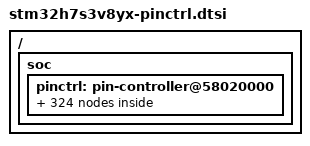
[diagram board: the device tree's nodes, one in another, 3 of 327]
/*
 * NOTE: Autogenerated file using genpinctrl.py
 *
 * SPDX-License-Identifier: Apache-2.0
 */

#include <zephyr/dt-bindings/pinctrl/stm32-pinctrl.h>

/ {
	soc {
		pinctrl: pin-controller@58020000 {

			/* ADC_IN / ADC_INN / ADC_INP */

			/omit-if-no-ref/ adc1_inn1_pa0: adc1_inn1_pa0 {
				pinmux = <STM32_PINMUX('A', 0, ANALOG)>;
			};

			/omit-if-no-ref/ adc1_inp0_pa0: adc1_inp0_pa0 {
				pinmux = <STM32_PINMUX('A', 0, ANALOG)>;
			};

			/omit-if-no-ref/ adc1_inp1_pa1: adc1_inp1_pa1 {
				pinmux = <STM32_PINMUX('A', 1, ANALOG)>;
			};

			/omit-if-no-ref/ adc1_inp14_pa2: adc1_inp14_pa2 {
				pinmux = <STM32_PINMUX('A', 2, ANALOG)>;
			};

			/omit-if-no-ref/ adc1_inp18_pa4: adc1_inp18_pa4 {
				pinmux = <STM32_PINMUX('A', 4, ANALOG)>;
			};

			/omit-if-no-ref/ adc1_inp3_pa6: adc1_inp3_pa6 {
				pinmux = <STM32_PINMUX('A', 6, ANALOG)>;
			};

			/omit-if-no-ref/ adc1_inn3_pa7: adc1_inn3_pa7 {
				pinmux = <STM32_PINMUX('A', 7, ANALOG)>;
			};

			/omit-if-no-ref/ adc1_inp7_pa7: adc1_inp7_pa7 {
				pinmux = <STM32_PINMUX('A', 7, ANALOG)>;
			};

			/omit-if-no-ref/ adc1_inn5_pb0: adc1_inn5_pb0 {
				pinmux = <STM32_PINMUX('B', 0, ANALOG)>;
			};

			/omit-if-no-ref/ adc1_inp9_pb0: adc1_inp9_pb0 {
				pinmux = <STM32_PINMUX('B', 0, ANALOG)>;
			};

			/omit-if-no-ref/ adc1_inp5_pb1: adc1_inp5_pb1 {
				pinmux = <STM32_PINMUX('B', 1, ANALOG)>;
			};

			/omit-if-no-ref/ adc1_inp10_pc0: adc1_inp10_pc0 {
				pinmux = <STM32_PINMUX('C', 0, ANALOG)>;
			};

			/omit-if-no-ref/ adc1_inn10_pc1: adc1_inn10_pc1 {
				pinmux = <STM32_PINMUX('C', 1, ANALOG)>;
			};

			/omit-if-no-ref/ adc1_inp11_pc1: adc1_inp11_pc1 {
				pinmux = <STM32_PINMUX('C', 1, ANALOG)>;
			};

			/omit-if-no-ref/ adc2_inn1_pa0: adc2_inn1_pa0 {
				pinmux = <STM32_PINMUX('A', 0, ANALOG)>;
			};

			/omit-if-no-ref/ adc2_inp0_pa0: adc2_inp0_pa0 {
				pinmux = <STM32_PINMUX('A', 0, ANALOG)>;
			};

			/omit-if-no-ref/ adc2_inp1_pa1: adc2_inp1_pa1 {
				pinmux = <STM32_PINMUX('A', 1, ANALOG)>;
			};

			/omit-if-no-ref/ adc2_inp14_pa2: adc2_inp14_pa2 {
				pinmux = <STM32_PINMUX('A', 2, ANALOG)>;
			};

			/omit-if-no-ref/ adc2_inp18_pa5: adc2_inp18_pa5 {
				pinmux = <STM32_PINMUX('A', 5, ANALOG)>;
			};

			/omit-if-no-ref/ adc2_inp3_pa6: adc2_inp3_pa6 {
				pinmux = <STM32_PINMUX('A', 6, ANALOG)>;
			};

			/omit-if-no-ref/ adc2_inn3_pa7: adc2_inn3_pa7 {
				pinmux = <STM32_PINMUX('A', 7, ANALOG)>;
			};

			/omit-if-no-ref/ adc2_inp7_pa7: adc2_inp7_pa7 {
				pinmux = <STM32_PINMUX('A', 7, ANALOG)>;
			};

			/omit-if-no-ref/ adc2_inn5_pb0: adc2_inn5_pb0 {
				pinmux = <STM32_PINMUX('B', 0, ANALOG)>;
			};

			/omit-if-no-ref/ adc2_inp9_pb0: adc2_inp9_pb0 {
				pinmux = <STM32_PINMUX('B', 0, ANALOG)>;
			};

			/omit-if-no-ref/ adc2_inp5_pb1: adc2_inp5_pb1 {
				pinmux = <STM32_PINMUX('B', 1, ANALOG)>;
			};

			/omit-if-no-ref/ adc2_inp10_pc0: adc2_inp10_pc0 {
				pinmux = <STM32_PINMUX('C', 0, ANALOG)>;
			};

			/omit-if-no-ref/ adc2_inn10_pc1: adc2_inn10_pc1 {
				pinmux = <STM32_PINMUX('C', 1, ANALOG)>;
			};

			/omit-if-no-ref/ adc2_inp11_pc1: adc2_inp11_pc1 {
				pinmux = <STM32_PINMUX('C', 1, ANALOG)>;
			};

			/* Analog */

			/omit-if-no-ref/ analog_pa0: analog_pa0 {
				pinmux = <STM32_PINMUX('A', 0, ANALOG)>;
			};

			/omit-if-no-ref/ analog_pa1: analog_pa1 {
				pinmux = <STM32_PINMUX('A', 1, ANALOG)>;
			};

			/omit-if-no-ref/ analog_pa2: analog_pa2 {
				pinmux = <STM32_PINMUX('A', 2, ANALOG)>;
			};

			/omit-if-no-ref/ analog_pa4: analog_pa4 {
				pinmux = <STM32_PINMUX('A', 4, ANALOG)>;
			};

			/omit-if-no-ref/ analog_pa5: analog_pa5 {
				pinmux = <STM32_PINMUX('A', 5, ANALOG)>;
			};

			/omit-if-no-ref/ analog_pa6: analog_pa6 {
				pinmux = <STM32_PINMUX('A', 6, ANALOG)>;
			};

			/omit-if-no-ref/ analog_pa7: analog_pa7 {
				pinmux = <STM32_PINMUX('A', 7, ANALOG)>;
			};

			/omit-if-no-ref/ analog_pa8: analog_pa8 {
				pinmux = <STM32_PINMUX('A', 8, ANALOG)>;
			};

			/omit-if-no-ref/ analog_pa9: analog_pa9 {
				pinmux = <STM32_PINMUX('A', 9, ANALOG)>;
			};

			/omit-if-no-ref/ analog_pa10: analog_pa10 {
				pinmux = <STM32_PINMUX('A', 10, ANALOG)>;
			};

			/omit-if-no-ref/ analog_pa11: analog_pa11 {
				pinmux = <STM32_PINMUX('A', 11, ANALOG)>;
			};

			/omit-if-no-ref/ analog_pa12: analog_pa12 {
				pinmux = <STM32_PINMUX('A', 12, ANALOG)>;
			};

			/omit-if-no-ref/ analog_pa13: analog_pa13 {
				pinmux = <STM32_PINMUX('A', 13, ANALOG)>;
			};

			/omit-if-no-ref/ analog_pa14: analog_pa14 {
				pinmux = <STM32_PINMUX('A', 14, ANALOG)>;
			};

			/omit-if-no-ref/ analog_pa15: analog_pa15 {
				pinmux = <STM32_PINMUX('A', 15, ANALOG)>;
			};

			/omit-if-no-ref/ analog_pb0: analog_pb0 {
				pinmux = <STM32_PINMUX('B', 0, ANALOG)>;
			};

			/omit-if-no-ref/ analog_pb1: analog_pb1 {
				pinmux = <STM32_PINMUX('B', 1, ANALOG)>;
			};

			/omit-if-no-ref/ analog_pb2: analog_pb2 {
				pinmux = <STM32_PINMUX('B', 2, ANALOG)>;
			};

			/omit-if-no-ref/ analog_pb3: analog_pb3 {
				pinmux = <STM32_PINMUX('B', 3, ANALOG)>;
			};

			/omit-if-no-ref/ analog_pb4: analog_pb4 {
				pinmux = <STM32_PINMUX('B', 4, ANALOG)>;
			};

			/omit-if-no-ref/ analog_pb5: analog_pb5 {
				pinmux = <STM32_PINMUX('B', 5, ANALOG)>;
			};

			/omit-if-no-ref/ analog_pb6: analog_pb6 {
				pinmux = <STM32_PINMUX('B', 6, ANALOG)>;
			};

			/omit-if-no-ref/ analog_pb7: analog_pb7 {
				pinmux = <STM32_PINMUX('B', 7, ANALOG)>;
			};

			/omit-if-no-ref/ analog_pb8: analog_pb8 {
				pinmux = <STM32_PINMUX('B', 8, ANALOG)>;
			};

			/omit-if-no-ref/ analog_pb10: analog_pb10 {
				pinmux = <STM32_PINMUX('B', 10, ANALOG)>;
			};

			/omit-if-no-ref/ analog_pb11: analog_pb11 {
				pinmux = <STM32_PINMUX('B', 11, ANALOG)>;
			};

			/omit-if-no-ref/ analog_pb12: analog_pb12 {
				pinmux = <STM32_PINMUX('B', 12, ANALOG)>;
			};

			/omit-if-no-ref/ analog_pb14: analog_pb14 {
				pinmux = <STM32_PINMUX('B', 14, ANALOG)>;
			};

			/omit-if-no-ref/ analog_pb15: analog_pb15 {
				pinmux = <STM32_PINMUX('B', 15, ANALOG)>;
			};

			/omit-if-no-ref/ analog_pc0: analog_pc0 {
				pinmux = <STM32_PINMUX('C', 0, ANALOG)>;
			};

			/omit-if-no-ref/ analog_pc1: analog_pc1 {
				pinmux = <STM32_PINMUX('C', 1, ANALOG)>;
			};

			/omit-if-no-ref/ analog_pc10: analog_pc10 {
				pinmux = <STM32_PINMUX('C', 10, ANALOG)>;
			};

			/omit-if-no-ref/ analog_pc11: analog_pc11 {
				pinmux = <STM32_PINMUX('C', 11, ANALOG)>;
			};

			/omit-if-no-ref/ analog_pc13: analog_pc13 {
				pinmux = <STM32_PINMUX('C', 13, ANALOG)>;
			};

			/omit-if-no-ref/ analog_pc14: analog_pc14 {
				pinmux = <STM32_PINMUX('C', 14, ANALOG)>;
			};

			/omit-if-no-ref/ analog_pc15: analog_pc15 {
				pinmux = <STM32_PINMUX('C', 15, ANALOG)>;
			};

			/omit-if-no-ref/ analog_pd7: analog_pd7 {
				pinmux = <STM32_PINMUX('D', 7, ANALOG)>;
			};

			/omit-if-no-ref/ analog_pd12: analog_pd12 {
				pinmux = <STM32_PINMUX('D', 12, ANALOG)>;
			};

			/omit-if-no-ref/ analog_ph0: analog_ph0 {
				pinmux = <STM32_PINMUX('H', 0, ANALOG)>;
			};

			/omit-if-no-ref/ analog_ph1: analog_ph1 {
				pinmux = <STM32_PINMUX('H', 1, ANALOG)>;
			};

			/omit-if-no-ref/ analog_pm0: analog_pm0 {
				pinmux = <STM32_PINMUX('M', 0, ANALOG)>;
			};

			/omit-if-no-ref/ analog_pm1: analog_pm1 {
				pinmux = <STM32_PINMUX('M', 1, ANALOG)>;
			};

			/omit-if-no-ref/ analog_pm2: analog_pm2 {
				pinmux = <STM32_PINMUX('M', 2, ANALOG)>;
			};

			/omit-if-no-ref/ analog_pm3: analog_pm3 {
				pinmux = <STM32_PINMUX('M', 3, ANALOG)>;
			};

			/omit-if-no-ref/ analog_pm5: analog_pm5 {
				pinmux = <STM32_PINMUX('M', 5, ANALOG)>;
			};

			/omit-if-no-ref/ analog_pm6: analog_pm6 {
				pinmux = <STM32_PINMUX('M', 6, ANALOG)>;
			};

			/omit-if-no-ref/ analog_pm8: analog_pm8 {
				pinmux = <STM32_PINMUX('M', 8, ANALOG)>;
			};

			/omit-if-no-ref/ analog_pm9: analog_pm9 {
				pinmux = <STM32_PINMUX('M', 9, ANALOG)>;
			};

			/omit-if-no-ref/ analog_pm11: analog_pm11 {
				pinmux = <STM32_PINMUX('M', 11, ANALOG)>;
			};

			/omit-if-no-ref/ analog_pm12: analog_pm12 {
				pinmux = <STM32_PINMUX('M', 12, ANALOG)>;
			};

			/omit-if-no-ref/ analog_pm13: analog_pm13 {
				pinmux = <STM32_PINMUX('M', 13, ANALOG)>;
			};

			/omit-if-no-ref/ analog_pm14: analog_pm14 {
				pinmux = <STM32_PINMUX('M', 14, ANALOG)>;
			};

			/omit-if-no-ref/ analog_po0: analog_po0 {
				pinmux = <STM32_PINMUX('O', 0, ANALOG)>;
			};

			/omit-if-no-ref/ analog_po1: analog_po1 {
				pinmux = <STM32_PINMUX('O', 1, ANALOG)>;
			};

			/omit-if-no-ref/ analog_po2: analog_po2 {
				pinmux = <STM32_PINMUX('O', 2, ANALOG)>;
			};

			/omit-if-no-ref/ analog_po4: analog_po4 {
				pinmux = <STM32_PINMUX('O', 4, ANALOG)>;
			};

			/omit-if-no-ref/ analog_po5: analog_po5 {
				pinmux = <STM32_PINMUX('O', 5, ANALOG)>;
			};

			/omit-if-no-ref/ analog_pp0: analog_pp0 {
				pinmux = <STM32_PINMUX('P', 0, ANALOG)>;
			};

			/omit-if-no-ref/ analog_pp1: analog_pp1 {
				pinmux = <STM32_PINMUX('P', 1, ANALOG)>;
			};

			/omit-if-no-ref/ analog_pp2: analog_pp2 {
				pinmux = <STM32_PINMUX('P', 2, ANALOG)>;
			};

			/omit-if-no-ref/ analog_pp3: analog_pp3 {
				pinmux = <STM32_PINMUX('P', 3, ANALOG)>;
			};

			/omit-if-no-ref/ analog_pp4: analog_pp4 {
				pinmux = <STM32_PINMUX('P', 4, ANALOG)>;
			};

			/omit-if-no-ref/ analog_pp5: analog_pp5 {
				pinmux = <STM32_PINMUX('P', 5, ANALOG)>;
			};

			/omit-if-no-ref/ analog_pp6: analog_pp6 {
				pinmux = <STM32_PINMUX('P', 6, ANALOG)>;
			};

			/omit-if-no-ref/ analog_pp7: analog_pp7 {
				pinmux = <STM32_PINMUX('P', 7, ANALOG)>;
			};

			/* FDCAN_RX */

			/omit-if-no-ref/ fdcan1_rx_pa11: fdcan1_rx_pa11 {
				pinmux = <STM32_PINMUX('A', 11, AF9)>;
			};

			/omit-if-no-ref/ fdcan1_rx_pb8: fdcan1_rx_pb8 {
				pinmux = <STM32_PINMUX('B', 8, AF9)>;
			};

			/omit-if-no-ref/ fdcan2_rx_pb5: fdcan2_rx_pb5 {
				pinmux = <STM32_PINMUX('B', 5, AF9)>;
			};

			/omit-if-no-ref/ fdcan2_rx_pb12: fdcan2_rx_pb12 {
				pinmux = <STM32_PINMUX('B', 12, AF9)>;
			};

			/* FDCAN_TX */

			/omit-if-no-ref/ fdcan1_tx_pa12: fdcan1_tx_pa12 {
				pinmux = <STM32_PINMUX('A', 12, AF9)>;
			};

			/omit-if-no-ref/ fdcan2_tx_pb1: fdcan2_tx_pb1 {
				pinmux = <STM32_PINMUX('B', 1, AF9)>;
			};

			/omit-if-no-ref/ fdcan2_tx_pb6: fdcan2_tx_pb6 {
				pinmux = <STM32_PINMUX('B', 6, AF9)>;
			};

			/* FMC */

			/omit-if-no-ref/ fmc_d7_pa0: fmc_d7_pa0 {
				pinmux = <STM32_PINMUX('A', 0, AF12)>;
				bias-pull-up;
				slew-rate = "very-high-speed";
			};

			/omit-if-no-ref/ fmc_d6_pa1: fmc_d6_pa1 {
				pinmux = <STM32_PINMUX('A', 1, AF12)>;
				bias-pull-up;
				slew-rate = "very-high-speed";
			};

			/omit-if-no-ref/ fmc_d5_pa2: fmc_d5_pa2 {
				pinmux = <STM32_PINMUX('A', 2, AF12)>;
				bias-pull-up;
				slew-rate = "very-high-speed";
			};

			/omit-if-no-ref/ fmc_noe_pa5: fmc_noe_pa5 {
				pinmux = <STM32_PINMUX('A', 5, AF12)>;
				bias-pull-up;
				slew-rate = "very-high-speed";
			};

			/omit-if-no-ref/ fmc_int_pa7: fmc_int_pa7 {
				pinmux = <STM32_PINMUX('A', 7, AF12)>;
				bias-pull-up;
				slew-rate = "very-high-speed";
			};

			/omit-if-no-ref/ fmc_d4_pa8: fmc_d4_pa8 {
				pinmux = <STM32_PINMUX('A', 8, AF12)>;
				bias-pull-up;
				slew-rate = "very-high-speed";
			};

			/omit-if-no-ref/ fmc_d3_pa9: fmc_d3_pa9 {
				pinmux = <STM32_PINMUX('A', 9, AF12)>;
				bias-pull-up;
				slew-rate = "very-high-speed";
			};

			/omit-if-no-ref/ fmc_d2_pa10: fmc_d2_pa10 {
				pinmux = <STM32_PINMUX('A', 10, AF12)>;
				bias-pull-up;
				slew-rate = "very-high-speed";
			};

			/omit-if-no-ref/ fmc_d1_pa11: fmc_d1_pa11 {
				pinmux = <STM32_PINMUX('A', 11, AF12)>;
				bias-pull-up;
				slew-rate = "very-high-speed";
			};

			/omit-if-no-ref/ fmc_d0_pa12: fmc_d0_pa12 {
				pinmux = <STM32_PINMUX('A', 12, AF12)>;
				bias-pull-up;
				slew-rate = "very-high-speed";
			};

			/omit-if-no-ref/ fmc_d15_pa15: fmc_d15_pa15 {
				pinmux = <STM32_PINMUX('A', 15, AF12)>;
				bias-pull-up;
				slew-rate = "very-high-speed";
			};

			/omit-if-no-ref/ fmc_noe_pb1: fmc_noe_pb1 {
				pinmux = <STM32_PINMUX('B', 1, AF12)>;
				bias-pull-up;
				slew-rate = "very-high-speed";
			};

			/omit-if-no-ref/ fmc_nwe_pb2: fmc_nwe_pb2 {
				pinmux = <STM32_PINMUX('B', 2, AF12)>;
				bias-pull-up;
				slew-rate = "very-high-speed";
			};

			/omit-if-no-ref/ fmc_d14_pb3: fmc_d14_pb3 {
				pinmux = <STM32_PINMUX('B', 3, AF12)>;
				bias-pull-up;
				slew-rate = "very-high-speed";
			};

			/omit-if-no-ref/ fmc_d13_pb4: fmc_d13_pb4 {
				pinmux = <STM32_PINMUX('B', 4, AF12)>;
				bias-pull-up;
				slew-rate = "very-high-speed";
			};

			/omit-if-no-ref/ fmc_d12_pb5: fmc_d12_pb5 {
				pinmux = <STM32_PINMUX('B', 5, AF12)>;
				bias-pull-up;
				slew-rate = "very-high-speed";
			};

			/omit-if-no-ref/ fmc_sdne1_pb6: fmc_sdne1_pb6 {
				pinmux = <STM32_PINMUX('B', 6, AF12)>;
				bias-pull-up;
				slew-rate = "very-high-speed";
			};

			/omit-if-no-ref/ fmc_sdcke1_pb7: fmc_sdcke1_pb7 {
				pinmux = <STM32_PINMUX('B', 7, AF12)>;
				bias-pull-up;
				slew-rate = "very-high-speed";
			};

			/omit-if-no-ref/ fmc_d9_pb8: fmc_d9_pb8 {
				pinmux = <STM32_PINMUX('B', 8, AF14)>;
				bias-pull-up;
				slew-rate = "very-high-speed";
			};

			/omit-if-no-ref/ fmc_d11_pb10: fmc_d11_pb10 {
				pinmux = <STM32_PINMUX('B', 10, AF12)>;
				bias-pull-up;
				slew-rate = "very-high-speed";
			};

			/omit-if-no-ref/ fmc_d10_pb11: fmc_d10_pb11 {
				pinmux = <STM32_PINMUX('B', 11, AF12)>;
				bias-pull-up;
				slew-rate = "very-high-speed";
			};

			/omit-if-no-ref/ fmc_d9_pb12: fmc_d9_pb12 {
				pinmux = <STM32_PINMUX('B', 12, AF12)>;
				bias-pull-up;
				slew-rate = "very-high-speed";
			};

			/omit-if-no-ref/ fmc_ne1_pb14: fmc_ne1_pb14 {
				pinmux = <STM32_PINMUX('B', 14, AF12)>;
				bias-pull-up;
				slew-rate = "very-high-speed";
			};

			/omit-if-no-ref/ fmc_a20_pb15: fmc_a20_pb15 {
				pinmux = <STM32_PINMUX('B', 15, AF12)>;
				bias-pull-up;
				slew-rate = "very-high-speed";
			};

			/omit-if-no-ref/ fmc_nbl1_pc0: fmc_nbl1_pc0 {
				pinmux = <STM32_PINMUX('C', 0, AF12)>;
				bias-pull-up;
				slew-rate = "very-high-speed";
			};

			/omit-if-no-ref/ fmc_a0_pc1: fmc_a0_pc1 {
				pinmux = <STM32_PINMUX('C', 1, AF12)>;
				bias-pull-up;
				slew-rate = "very-high-speed";
			};

			/omit-if-no-ref/ fmc_a16_pc1: fmc_a16_pc1 {
				pinmux = <STM32_PINMUX('C', 1, AF7)>;
				bias-pull-up;
				slew-rate = "very-high-speed";
			};

			/omit-if-no-ref/ fmc_d8_pd7: fmc_d8_pd7 {
				pinmux = <STM32_PINMUX('D', 7, AF12)>;
				bias-pull-up;
				slew-rate = "very-high-speed";
			};

			/omit-if-no-ref/ fmc_ne1_pd12: fmc_ne1_pd12 {
				pinmux = <STM32_PINMUX('D', 12, AF12)>;
				bias-pull-up;
				slew-rate = "very-high-speed";
			};

			/* I2C_SCL */

			/omit-if-no-ref/ i2c1_scl_pb6: i2c1_scl_pb6 {
				pinmux = <STM32_PINMUX('B', 6, AF4)>;
				bias-pull-up;
				drive-open-drain;
			};

			/omit-if-no-ref/ i2c1_scl_pb8: i2c1_scl_pb8 {
				pinmux = <STM32_PINMUX('B', 8, AF4)>;
				bias-pull-up;
				drive-open-drain;
			};

			/omit-if-no-ref/ i2c2_scl_pb10: i2c2_scl_pb10 {
				pinmux = <STM32_PINMUX('B', 10, AF4)>;
				bias-pull-up;
				drive-open-drain;
			};

			/omit-if-no-ref/ i2c3_scl_pa8: i2c3_scl_pa8 {
				pinmux = <STM32_PINMUX('A', 8, AF4)>;
				bias-pull-up;
				drive-open-drain;
			};

			/* I2C_SDA */

			/omit-if-no-ref/ i2c1_sda_pb7: i2c1_sda_pb7 {
				pinmux = <STM32_PINMUX('B', 7, AF4)>;
				bias-pull-up;
				drive-open-drain;
			};

			/omit-if-no-ref/ i2c2_sda_pb11: i2c2_sda_pb11 {
				pinmux = <STM32_PINMUX('B', 11, AF4)>;
				bias-pull-up;
				drive-open-drain;
			};

			/omit-if-no-ref/ i2c3_sda_pa9: i2c3_sda_pa9 {
				pinmux = <STM32_PINMUX('A', 9, AF4)>;
				bias-pull-up;
				drive-open-drain;
			};

			/* I2C_SMBA */

			/omit-if-no-ref/ i2c1_smba_pb5: i2c1_smba_pb5 {
				pinmux = <STM32_PINMUX('B', 5, AF4)>;
				bias-pull-up;
			};

			/omit-if-no-ref/ i2c2_smba_pb12: i2c2_smba_pb12 {
				pinmux = <STM32_PINMUX('B', 12, AF4)>;
				bias-pull-up;
			};

			/* I2S_CK */

			/omit-if-no-ref/ i2s1_ck_pa5: i2s1_ck_pa5 {
				pinmux = <STM32_PINMUX('A', 5, AF5)>;
				slew-rate = "very-high-speed";
			};

			/omit-if-no-ref/ i2s1_ck_pb0: i2s1_ck_pb0 {
				pinmux = <STM32_PINMUX('B', 0, AF5)>;
				slew-rate = "very-high-speed";
			};

			/omit-if-no-ref/ i2s1_ck_pb3: i2s1_ck_pb3 {
				pinmux = <STM32_PINMUX('B', 3, AF5)>;
				slew-rate = "very-high-speed";
			};

			/omit-if-no-ref/ i2s2_ck_pa9: i2s2_ck_pa9 {
				pinmux = <STM32_PINMUX('A', 9, AF5)>;
				slew-rate = "very-high-speed";
			};

			/omit-if-no-ref/ i2s2_ck_pa12: i2s2_ck_pa12 {
				pinmux = <STM32_PINMUX('A', 12, AF5)>;
				slew-rate = "very-high-speed";
			};

			/omit-if-no-ref/ i2s2_ck_pb10: i2s2_ck_pb10 {
				pinmux = <STM32_PINMUX('B', 10, AF5)>;
				slew-rate = "very-high-speed";
			};

			/omit-if-no-ref/ i2s3_ck_pb3: i2s3_ck_pb3 {
				pinmux = <STM32_PINMUX('B', 3, AF6)>;
				slew-rate = "very-high-speed";
			};

			/omit-if-no-ref/ i2s3_ck_pc10: i2s3_ck_pc10 {
				pinmux = <STM32_PINMUX('C', 10, AF6)>;
				slew-rate = "very-high-speed";
			};

			/omit-if-no-ref/ i2s6_ck_pa5: i2s6_ck_pa5 {
				pinmux = <STM32_PINMUX('A', 5, AF8)>;
				slew-rate = "very-high-speed";
			};

			/omit-if-no-ref/ i2s6_ck_pb3: i2s6_ck_pb3 {
				pinmux = <STM32_PINMUX('B', 3, AF8)>;
				slew-rate = "very-high-speed";
			};

			/* I2S_WS */

			/omit-if-no-ref/ i2s1_ws_pa4: i2s1_ws_pa4 {
				pinmux = <STM32_PINMUX('A', 4, AF5)>;
			};

			/omit-if-no-ref/ i2s1_ws_pa15: i2s1_ws_pa15 {
				pinmux = <STM32_PINMUX('A', 15, AF5)>;
			};

			/omit-if-no-ref/ i2s2_ws_pa11: i2s2_ws_pa11 {
				pinmux = <STM32_PINMUX('A', 11, AF5)>;
			};

			/omit-if-no-ref/ i2s2_ws_pb4: i2s2_ws_pb4 {
				pinmux = <STM32_PINMUX('B', 4, AF7)>;
			};

			/omit-if-no-ref/ i2s2_ws_pb12: i2s2_ws_pb12 {
				pinmux = <STM32_PINMUX('B', 12, AF5)>;
			};

			/omit-if-no-ref/ i2s3_ws_pa4: i2s3_ws_pa4 {
				pinmux = <STM32_PINMUX('A', 4, AF6)>;
			};

			/omit-if-no-ref/ i2s3_ws_pa15: i2s3_ws_pa15 {
				pinmux = <STM32_PINMUX('A', 15, AF6)>;
			};

			/omit-if-no-ref/ i2s6_ws_pa0: i2s6_ws_pa0 {
				pinmux = <STM32_PINMUX('A', 0, AF5)>;
			};

			/omit-if-no-ref/ i2s6_ws_pa4: i2s6_ws_pa4 {
				pinmux = <STM32_PINMUX('A', 4, AF8)>;
			};

			/omit-if-no-ref/ i2s6_ws_pa15: i2s6_ws_pa15 {
				pinmux = <STM32_PINMUX('A', 15, AF7)>;
			};

			/* I3C_SCL */

			/omit-if-no-ref/ i3c1_scl_pb6: i3c1_scl_pb6 {
				pinmux = <STM32_PINMUX('B', 6, AF4)>;
				slew-rate = "very-high-speed";
			};

			/omit-if-no-ref/ i3c1_scl_pb8: i3c1_scl_pb8 {
				pinmux = <STM32_PINMUX('B', 8, AF4)>;
				slew-rate = "very-high-speed";
			};

			/* I3C_SDA */

			/omit-if-no-ref/ i3c1_sda_pb7: i3c1_sda_pb7 {
				pinmux = <STM32_PINMUX('B', 7, AF4)>;
				slew-rate = "very-high-speed";
			};

			/* JTAG PORT */

			/omit-if-no-ref/ debug_jtms_swdio_pa13: debug_jtms_swdio_pa13 {
				pinmux = <STM32_PINMUX('A', 13, AF0)>;
			};

			/omit-if-no-ref/ debug_jtck_swclk_pa14: debug_jtck_swclk_pa14 {
				pinmux = <STM32_PINMUX('A', 14, AF0)>;
			};

			/omit-if-no-ref/ debug_jtdi_pa15: debug_jtdi_pa15 {
				pinmux = <STM32_PINMUX('A', 15, AF0)>;
			};

			/omit-if-no-ref/ debug_jtdo_swo_pb3: debug_jtdo_swo_pb3 {
				pinmux = <STM32_PINMUX('B', 3, AF0)>;
			};

			/omit-if-no-ref/ debug_njtrst_pb4: debug_njtrst_pb4 {
				pinmux = <STM32_PINMUX('B', 4, AF0)>;
			};

			/* RCC_MCO */

			/omit-if-no-ref/ rcc_mco_1_pa8: rcc_mco_1_pa8 {
				pinmux = <STM32_PINMUX('A', 8, AF0)>;
				slew-rate = "very-high-speed";
			};

			/* SAI */

			/omit-if-no-ref/ sai2_sd_b_pa0: sai2_sd_b_pa0 {
				pinmux = <STM32_PINMUX('A', 0, AF10)>;
			};

			/omit-if-no-ref/ sai2_mclk_b_pa1: sai2_mclk_b_pa1 {
				pinmux = <STM32_PINMUX('A', 1, AF10)>;
			};

			/omit-if-no-ref/ sai2_sck_b_pa2: sai2_sck_b_pa2 {
				pinmux = <STM32_PINMUX('A', 2, AF8)>;
			};

			/omit-if-no-ref/ sai2_fs_b_pa12: sai2_fs_b_pa12 {
				pinmux = <STM32_PINMUX('A', 12, AF8)>;
			};

			/omit-if-no-ref/ sai2_fs_b_pc0: sai2_fs_b_pc0 {
				pinmux = <STM32_PINMUX('C', 0, AF8)>;
			};

			/omit-if-no-ref/ sai2_fs_a_pd12: sai2_fs_a_pd12 {
				pinmux = <STM32_PINMUX('D', 12, AF10)>;
			};

			/* SDMMC */

			/omit-if-no-ref/ sdmmc2_cmd_pa0: sdmmc2_cmd_pa0 {
				pinmux = <STM32_PINMUX('A', 0, AF9)>;
				bias-pull-up;
				slew-rate = "very-high-speed";
			};

			/omit-if-no-ref/ sdmmc2_d2_pb3: sdmmc2_d2_pb3 {
				pinmux = <STM32_PINMUX('B', 3, AF9)>;
				bias-pull-up;
				slew-rate = "very-high-speed";
			};

			/omit-if-no-ref/ sdmmc2_d3_pb4: sdmmc2_d3_pb4 {
				pinmux = <STM32_PINMUX('B', 4, AF9)>;
				bias-pull-up;
				slew-rate = "very-high-speed";
			};

			/omit-if-no-ref/ sdmmc2_d4_pb8: sdmmc2_d4_pb8 {
				pinmux = <STM32_PINMUX('B', 8, AF10)>;
				bias-pull-up;
				slew-rate = "very-high-speed";
			};

			/omit-if-no-ref/ sdmmc2_d0_pb14: sdmmc2_d0_pb14 {
				pinmux = <STM32_PINMUX('B', 14, AF9)>;
				bias-pull-up;
				slew-rate = "very-high-speed";
			};

			/omit-if-no-ref/ sdmmc2_d1_pb15: sdmmc2_d1_pb15 {
				pinmux = <STM32_PINMUX('B', 15, AF9)>;
				bias-pull-up;
				slew-rate = "very-high-speed";
			};

			/omit-if-no-ref/ sdmmc2_ck_pc1: sdmmc2_ck_pc1 {
				pinmux = <STM32_PINMUX('C', 1, AF9)>;
				bias-pull-up;
				slew-rate = "very-high-speed";
			};

			/omit-if-no-ref/ sdmmc2_cmd_pd7: sdmmc2_cmd_pd7 {
				pinmux = <STM32_PINMUX('D', 7, AF11)>;
				bias-pull-up;
				slew-rate = "very-high-speed";
			};

			/* SPI_MISO */

			/omit-if-no-ref/ spi1_miso_pa6: spi1_miso_pa6 {
				pinmux = <STM32_PINMUX('A', 6, AF5)>;
				bias-pull-down;
			};

			/omit-if-no-ref/ spi1_miso_pb4: spi1_miso_pb4 {
				pinmux = <STM32_PINMUX('B', 4, AF5)>;
				bias-pull-down;
			};

			/omit-if-no-ref/ spi2_miso_pb14: spi2_miso_pb14 {
				pinmux = <STM32_PINMUX('B', 14, AF5)>;
				bias-pull-down;
			};

			/omit-if-no-ref/ spi3_miso_pb4: spi3_miso_pb4 {
				pinmux = <STM32_PINMUX('B', 4, AF6)>;
				bias-pull-down;
			};

			/omit-if-no-ref/ spi3_miso_pc11: spi3_miso_pc11 {
				pinmux = <STM32_PINMUX('C', 11, AF6)>;
				bias-pull-down;
			};

			/omit-if-no-ref/ spi5_miso_pm14: spi5_miso_pm14 {
				pinmux = <STM32_PINMUX('M', 14, AF5)>;
				bias-pull-down;
			};

			/omit-if-no-ref/ spi6_miso_pa6: spi6_miso_pa6 {
				pinmux = <STM32_PINMUX('A', 6, AF8)>;
				bias-pull-down;
			};

			/omit-if-no-ref/ spi6_miso_pb4: spi6_miso_pb4 {
				pinmux = <STM32_PINMUX('B', 4, AF8)>;
				bias-pull-down;
			};

			/* SPI_MOSI */

			/omit-if-no-ref/ spi1_mosi_pa7: spi1_mosi_pa7 {
				pinmux = <STM32_PINMUX('A', 7, AF5)>;
				bias-pull-down;
			};

			/omit-if-no-ref/ spi1_mosi_pb5: spi1_mosi_pb5 {
				pinmux = <STM32_PINMUX('B', 5, AF5)>;
				bias-pull-down;
			};

			/omit-if-no-ref/ spi1_mosi_pd7: spi1_mosi_pd7 {
				pinmux = <STM32_PINMUX('D', 7, AF5)>;
				bias-pull-down;
			};

			/omit-if-no-ref/ spi2_mosi_pb15: spi2_mosi_pb15 {
				pinmux = <STM32_PINMUX('B', 15, AF5)>;
				bias-pull-down;
			};

			/omit-if-no-ref/ spi2_mosi_pc1: spi2_mosi_pc1 {
				pinmux = <STM32_PINMUX('C', 1, AF5)>;
				bias-pull-down;
			};

			/omit-if-no-ref/ spi3_mosi_pb2: spi3_mosi_pb2 {
				pinmux = <STM32_PINMUX('B', 2, AF7)>;
				bias-pull-down;
			};

			/omit-if-no-ref/ spi3_mosi_pb5: spi3_mosi_pb5 {
				pinmux = <STM32_PINMUX('B', 5, AF7)>;
				bias-pull-down;
			};

			/omit-if-no-ref/ spi5_mosi_pm13: spi5_mosi_pm13 {
				pinmux = <STM32_PINMUX('M', 13, AF5)>;
				bias-pull-down;
			};

			/omit-if-no-ref/ spi6_mosi_pa7: spi6_mosi_pa7 {
				pinmux = <STM32_PINMUX('A', 7, AF8)>;
				bias-pull-down;
			};

			/omit-if-no-ref/ spi6_mosi_pb5: spi6_mosi_pb5 {
				pinmux = <STM32_PINMUX('B', 5, AF8)>;
				bias-pull-down;
			};

			/* SPI_NSS */

			/omit-if-no-ref/ spi1_nss_pa4: spi1_nss_pa4 {
				pinmux = <STM32_PINMUX('A', 4, AF5)>;
				bias-pull-up;
			};

			/omit-if-no-ref/ spi1_nss_pa15: spi1_nss_pa15 {
				pinmux = <STM32_PINMUX('A', 15, AF5)>;
				bias-pull-up;
			};

			/omit-if-no-ref/ spi2_nss_pa11: spi2_nss_pa11 {
				pinmux = <STM32_PINMUX('A', 11, AF5)>;
				bias-pull-up;
			};

			/omit-if-no-ref/ spi2_nss_pb4: spi2_nss_pb4 {
				pinmux = <STM32_PINMUX('B', 4, AF7)>;
				bias-pull-up;
			};

			/omit-if-no-ref/ spi2_nss_pb12: spi2_nss_pb12 {
				pinmux = <STM32_PINMUX('B', 12, AF5)>;
				bias-pull-up;
			};

			/omit-if-no-ref/ spi3_nss_pa4: spi3_nss_pa4 {
				pinmux = <STM32_PINMUX('A', 4, AF6)>;
				bias-pull-up;
			};

			/omit-if-no-ref/ spi3_nss_pa15: spi3_nss_pa15 {
				pinmux = <STM32_PINMUX('A', 15, AF6)>;
				bias-pull-up;
			};

			/omit-if-no-ref/ spi5_nss_pm12: spi5_nss_pm12 {
				pinmux = <STM32_PINMUX('M', 12, AF5)>;
				bias-pull-up;
			};

			/omit-if-no-ref/ spi6_nss_pa0: spi6_nss_pa0 {
				pinmux = <STM32_PINMUX('A', 0, AF5)>;
				bias-pull-up;
			};

			/omit-if-no-ref/ spi6_nss_pa4: spi6_nss_pa4 {
				pinmux = <STM32_PINMUX('A', 4, AF8)>;
				bias-pull-up;
			};

			/omit-if-no-ref/ spi6_nss_pa15: spi6_nss_pa15 {
				pinmux = <STM32_PINMUX('A', 15, AF7)>;
				bias-pull-up;
			};

			/* SPI_SCK */

			/omit-if-no-ref/ spi1_sck_pa5: spi1_sck_pa5 {
				pinmux = <STM32_PINMUX('A', 5, AF5)>;
				bias-pull-down;
				slew-rate = "very-high-speed";
			};

			/omit-if-no-ref/ spi1_sck_pb0: spi1_sck_pb0 {
				pinmux = <STM32_PINMUX('B', 0, AF5)>;
				bias-pull-down;
				slew-rate = "very-high-speed";
			};

			/omit-if-no-ref/ spi1_sck_pb3: spi1_sck_pb3 {
				pinmux = <STM32_PINMUX('B', 3, AF5)>;
				bias-pull-down;
				slew-rate = "very-high-speed";
			};

			/omit-if-no-ref/ spi2_sck_pa9: spi2_sck_pa9 {
				pinmux = <STM32_PINMUX('A', 9, AF5)>;
				bias-pull-down;
				slew-rate = "very-high-speed";
			};

			/omit-if-no-ref/ spi2_sck_pa12: spi2_sck_pa12 {
				pinmux = <STM32_PINMUX('A', 12, AF5)>;
				bias-pull-down;
				slew-rate = "very-high-speed";
			};

			/omit-if-no-ref/ spi2_sck_pb10: spi2_sck_pb10 {
				pinmux = <STM32_PINMUX('B', 10, AF5)>;
				bias-pull-down;
				slew-rate = "very-high-speed";
			};

			/omit-if-no-ref/ spi3_sck_pb3: spi3_sck_pb3 {
				pinmux = <STM32_PINMUX('B', 3, AF6)>;
				bias-pull-down;
				slew-rate = "very-high-speed";
			};

			/omit-if-no-ref/ spi3_sck_pc10: spi3_sck_pc10 {
				pinmux = <STM32_PINMUX('C', 10, AF6)>;
				bias-pull-down;
				slew-rate = "very-high-speed";
			};

			/omit-if-no-ref/ spi5_sck_pm11: spi5_sck_pm11 {
				pinmux = <STM32_PINMUX('M', 11, AF5)>;
				bias-pull-down;
				slew-rate = "very-high-speed";
			};

			/omit-if-no-ref/ spi6_sck_pa5: spi6_sck_pa5 {
				pinmux = <STM32_PINMUX('A', 5, AF8)>;
				bias-pull-down;
				slew-rate = "very-high-speed";
			};

			/omit-if-no-ref/ spi6_sck_pb3: spi6_sck_pb3 {
				pinmux = <STM32_PINMUX('B', 3, AF8)>;
				bias-pull-down;
				slew-rate = "very-high-speed";
			};

			/* TIM_BKIN */

			/omit-if-no-ref/ tim1_bkin_pa6: tim1_bkin_pa6 {
				pinmux = <STM32_PINMUX('A', 6, AF1)>;
			};

			/omit-if-no-ref/ tim1_bkin_pb12: tim1_bkin_pb12 {
				pinmux = <STM32_PINMUX('B', 12, AF1)>;
			};

			/omit-if-no-ref/ tim1_bkin_pc10: tim1_bkin_pc10 {
				pinmux = <STM32_PINMUX('C', 10, AF1)>;
			};

			/omit-if-no-ref/ tim16_bkin_pb4: tim16_bkin_pb4 {
				pinmux = <STM32_PINMUX('B', 4, AF1)>;
			};

			/* TIM_CH / TIM_CHN */

			/omit-if-no-ref/ tim1_ch1n_pa7: tim1_ch1n_pa7 {
				pinmux = <STM32_PINMUX('A', 7, AF1)>;
			};

			/omit-if-no-ref/ tim1_ch1_pa8: tim1_ch1_pa8 {
				pinmux = <STM32_PINMUX('A', 8, AF1)>;
			};

			/omit-if-no-ref/ tim1_ch2_pa9: tim1_ch2_pa9 {
				pinmux = <STM32_PINMUX('A', 9, AF1)>;
			};

			/omit-if-no-ref/ tim1_ch3_pa10: tim1_ch3_pa10 {
				pinmux = <STM32_PINMUX('A', 10, AF1)>;
			};

			/omit-if-no-ref/ tim1_ch4_pa11: tim1_ch4_pa11 {
				pinmux = <STM32_PINMUX('A', 11, AF1)>;
			};

			/omit-if-no-ref/ tim1_ch2n_pb0: tim1_ch2n_pb0 {
				pinmux = <STM32_PINMUX('B', 0, AF1)>;
			};

			/omit-if-no-ref/ tim1_ch3n_pb1: tim1_ch3n_pb1 {
				pinmux = <STM32_PINMUX('B', 1, AF1)>;
			};

			/omit-if-no-ref/ tim1_ch2n_pb14: tim1_ch2n_pb14 {
				pinmux = <STM32_PINMUX('B', 14, AF1)>;
			};

			/omit-if-no-ref/ tim1_ch3n_pb15: tim1_ch3n_pb15 {
				pinmux = <STM32_PINMUX('B', 15, AF1)>;
			};

			/omit-if-no-ref/ tim2_ch1_pa0: tim2_ch1_pa0 {
				pinmux = <STM32_PINMUX('A', 0, AF1)>;
			};

			/omit-if-no-ref/ tim2_ch2_pa1: tim2_ch2_pa1 {
				pinmux = <STM32_PINMUX('A', 1, AF1)>;
			};

			/omit-if-no-ref/ tim2_ch3_pa2: tim2_ch3_pa2 {
				pinmux = <STM32_PINMUX('A', 2, AF1)>;
			};

			/omit-if-no-ref/ tim2_ch1_pa5: tim2_ch1_pa5 {
				pinmux = <STM32_PINMUX('A', 5, AF1)>;
			};

			/omit-if-no-ref/ tim2_ch1_pa15: tim2_ch1_pa15 {
				pinmux = <STM32_PINMUX('A', 15, AF1)>;
			};

			/omit-if-no-ref/ tim2_ch2_pb3: tim2_ch2_pb3 {
				pinmux = <STM32_PINMUX('B', 3, AF1)>;
			};

			/omit-if-no-ref/ tim2_ch3_pb10: tim2_ch3_pb10 {
				pinmux = <STM32_PINMUX('B', 10, AF1)>;
			};

			/omit-if-no-ref/ tim2_ch4_pb11: tim2_ch4_pb11 {
				pinmux = <STM32_PINMUX('B', 11, AF1)>;
			};

			/omit-if-no-ref/ tim12_ch1_pb14: tim12_ch1_pb14 {
				pinmux = <STM32_PINMUX('B', 14, AF2)>;
			};

			/omit-if-no-ref/ tim12_ch2_pb15: tim12_ch2_pb15 {
				pinmux = <STM32_PINMUX('B', 15, AF2)>;
			};

			/omit-if-no-ref/ tim13_ch1_pa6: tim13_ch1_pa6 {
				pinmux = <STM32_PINMUX('A', 6, AF9)>;
			};

			/omit-if-no-ref/ tim14_ch1_pa7: tim14_ch1_pa7 {
				pinmux = <STM32_PINMUX('A', 7, AF9)>;
			};

			/omit-if-no-ref/ tim16_ch1n_pb6: tim16_ch1n_pb6 {
				pinmux = <STM32_PINMUX('B', 6, AF1)>;
			};

			/omit-if-no-ref/ tim16_ch1_pb8: tim16_ch1_pb8 {
				pinmux = <STM32_PINMUX('B', 8, AF1)>;
			};

			/omit-if-no-ref/ tim9_ch1_pa0: tim9_ch1_pa0 {
				pinmux = <STM32_PINMUX('A', 0, AF3)>;
			};

			/omit-if-no-ref/ tim9_ch2_pa5: tim9_ch2_pa5 {
				pinmux = <STM32_PINMUX('A', 5, AF3)>;
			};

			/omit-if-no-ref/ tim9_ch1_pb0: tim9_ch1_pb0 {
				pinmux = <STM32_PINMUX('B', 0, AF3)>;
			};

			/omit-if-no-ref/ tim9_ch2_pb1: tim9_ch2_pb1 {
				pinmux = <STM32_PINMUX('B', 1, AF3)>;
			};

			/* UART_CTS / USART_CTS / LPUART_CTS */

			/omit-if-no-ref/ lpuart1_cts_pa11: lpuart1_cts_pa11 {
				pinmux = <STM32_PINMUX('A', 11, AF3)>;
				bias-pull-up;
			};

			/omit-if-no-ref/ usart1_cts_pa11: usart1_cts_pa11 {
				pinmux = <STM32_PINMUX('A', 11, AF7)>;
				bias-pull-up;
			};

			/omit-if-no-ref/ uart4_cts_pb0: uart4_cts_pb0 {
				pinmux = <STM32_PINMUX('B', 0, AF8)>;
				bias-pull-up;
			};

			/omit-if-no-ref/ uart4_cts_pb15: uart4_cts_pb15 {
				pinmux = <STM32_PINMUX('B', 15, AF8)>;
				bias-pull-up;
			};

			/* UART_DE / USART_DE / LPUART_DE */

			/omit-if-no-ref/ lpuart1_de_pa12: lpuart1_de_pa12 {
				pinmux = <STM32_PINMUX('A', 12, AF3)>;
				drive-push-pull;
			};

			/omit-if-no-ref/ usart1_de_pa12: usart1_de_pa12 {
				pinmux = <STM32_PINMUX('A', 12, AF7)>;
				drive-push-pull;
			};

			/omit-if-no-ref/ usart3_de_pb14: usart3_de_pb14 {
				pinmux = <STM32_PINMUX('B', 14, AF7)>;
				drive-push-pull;
			};

			/omit-if-no-ref/ usart3_de_pd12: usart3_de_pd12 {
				pinmux = <STM32_PINMUX('D', 12, AF7)>;
				drive-push-pull;
			};

			/omit-if-no-ref/ uart4_de_pa15: uart4_de_pa15 {
				pinmux = <STM32_PINMUX('A', 15, AF8)>;
				drive-push-pull;
			};

			/omit-if-no-ref/ uart4_de_pb14: uart4_de_pb14 {
				pinmux = <STM32_PINMUX('B', 14, AF8)>;
				drive-push-pull;
			};

			/* UART_RTS / USART_RTS / LPUART_RTS */

			/omit-if-no-ref/ lpuart1_rts_pa12: lpuart1_rts_pa12 {
				pinmux = <STM32_PINMUX('A', 12, AF3)>;
				drive-push-pull;
			};

			/omit-if-no-ref/ usart1_rts_pa12: usart1_rts_pa12 {
				pinmux = <STM32_PINMUX('A', 12, AF7)>;
				drive-push-pull;
			};

			/omit-if-no-ref/ usart3_rts_pb14: usart3_rts_pb14 {
				pinmux = <STM32_PINMUX('B', 14, AF7)>;
				drive-push-pull;
			};

			/omit-if-no-ref/ usart3_rts_pd12: usart3_rts_pd12 {
				pinmux = <STM32_PINMUX('D', 12, AF7)>;
				drive-push-pull;
			};

			/omit-if-no-ref/ uart4_rts_pa15: uart4_rts_pa15 {
				pinmux = <STM32_PINMUX('A', 15, AF8)>;
				drive-push-pull;
			};

			/omit-if-no-ref/ uart4_rts_pb14: uart4_rts_pb14 {
				pinmux = <STM32_PINMUX('B', 14, AF8)>;
				drive-push-pull;
			};

			/* UART_RX / USART_RX / LPUART_RX */

			/omit-if-no-ref/ lpuart1_rx_pa10: lpuart1_rx_pa10 {
				pinmux = <STM32_PINMUX('A', 10, AF3)>;
			};

			/omit-if-no-ref/ usart1_rx_pa10: usart1_rx_pa10 {
				pinmux = <STM32_PINMUX('A', 10, AF7)>;
			};

			/omit-if-no-ref/ lpuart1_rx_pb7: lpuart1_rx_pb7 {
				pinmux = <STM32_PINMUX('B', 7, AF8)>;
			};

			/omit-if-no-ref/ usart1_rx_pb7: usart1_rx_pb7 {
				pinmux = <STM32_PINMUX('B', 7, AF7)>;
			};

			/omit-if-no-ref/ usart1_rx_pb15: usart1_rx_pb15 {
				pinmux = <STM32_PINMUX('B', 15, AF4)>;
			};

			/omit-if-no-ref/ usart3_rx_pb11: usart3_rx_pb11 {
				pinmux = <STM32_PINMUX('B', 11, AF7)>;
			};

			/omit-if-no-ref/ usart3_rx_pc11: usart3_rx_pc11 {
				pinmux = <STM32_PINMUX('C', 11, AF7)>;
			};

			/omit-if-no-ref/ uart4_rx_pa1: uart4_rx_pa1 {
				pinmux = <STM32_PINMUX('A', 1, AF8)>;
			};

			/omit-if-no-ref/ uart4_rx_pa11: uart4_rx_pa11 {
				pinmux = <STM32_PINMUX('A', 11, AF6)>;
			};

			/omit-if-no-ref/ uart4_rx_pb8: uart4_rx_pb8 {
				pinmux = <STM32_PINMUX('B', 8, AF8)>;
			};

			/omit-if-no-ref/ uart4_rx_pc11: uart4_rx_pc11 {
				pinmux = <STM32_PINMUX('C', 11, AF8)>;
			};

			/omit-if-no-ref/ uart5_rx_pb5: uart5_rx_pb5 {
				pinmux = <STM32_PINMUX('B', 5, AF14)>;
			};

			/omit-if-no-ref/ uart5_rx_pb12: uart5_rx_pb12 {
				pinmux = <STM32_PINMUX('B', 12, AF14)>;
			};

			/omit-if-no-ref/ uart7_rx_pa8: uart7_rx_pa8 {
				pinmux = <STM32_PINMUX('A', 8, AF11)>;
			};

			/omit-if-no-ref/ uart7_rx_pb3: uart7_rx_pb3 {
				pinmux = <STM32_PINMUX('B', 3, AF11)>;
			};

			/omit-if-no-ref/ uart7_rx_pm8: uart7_rx_pm8 {
				pinmux = <STM32_PINMUX('M', 8, AF7)>;
			};

			/* UART_TX / USART_TX / LPUART_TX */

			/omit-if-no-ref/ lpuart1_tx_pa9: lpuart1_tx_pa9 {
				pinmux = <STM32_PINMUX('A', 9, AF3)>;
				bias-pull-up;
			};

			/omit-if-no-ref/ usart1_tx_pa9: usart1_tx_pa9 {
				pinmux = <STM32_PINMUX('A', 9, AF7)>;
				bias-pull-up;
			};

			/omit-if-no-ref/ lpuart1_tx_pb6: lpuart1_tx_pb6 {
				pinmux = <STM32_PINMUX('B', 6, AF8)>;
				bias-pull-up;
			};

			/omit-if-no-ref/ usart1_tx_pb6: usart1_tx_pb6 {
				pinmux = <STM32_PINMUX('B', 6, AF7)>;
				bias-pull-up;
			};

			/omit-if-no-ref/ usart1_tx_pb14: usart1_tx_pb14 {
				pinmux = <STM32_PINMUX('B', 14, AF4)>;
				bias-pull-up;
			};

			/omit-if-no-ref/ usart3_tx_pb10: usart3_tx_pb10 {
				pinmux = <STM32_PINMUX('B', 10, AF7)>;
				bias-pull-up;
			};

			/omit-if-no-ref/ usart3_tx_pc10: usart3_tx_pc10 {
				pinmux = <STM32_PINMUX('C', 10, AF7)>;
				bias-pull-up;
			};

			/omit-if-no-ref/ uart4_tx_pa0: uart4_tx_pa0 {
				pinmux = <STM32_PINMUX('A', 0, AF8)>;
				bias-pull-up;
			};

			/omit-if-no-ref/ uart4_tx_pa12: uart4_tx_pa12 {
				pinmux = <STM32_PINMUX('A', 12, AF6)>;
				bias-pull-up;
			};

			/omit-if-no-ref/ uart4_tx_pc10: uart4_tx_pc10 {
				pinmux = <STM32_PINMUX('C', 10, AF8)>;
				bias-pull-up;
			};

			/omit-if-no-ref/ uart5_tx_pb6: uart5_tx_pb6 {
				pinmux = <STM32_PINMUX('B', 6, AF14)>;
				bias-pull-up;
			};

			/omit-if-no-ref/ uart5_tx_pb7: uart5_tx_pb7 {
				pinmux = <STM32_PINMUX('B', 7, AF14)>;
				bias-pull-up;
			};

			/omit-if-no-ref/ uart7_tx_pa15: uart7_tx_pa15 {
				pinmux = <STM32_PINMUX('A', 15, AF11)>;
				bias-pull-up;
			};

			/omit-if-no-ref/ uart7_tx_pb4: uart7_tx_pb4 {
				pinmux = <STM32_PINMUX('B', 4, AF11)>;
				bias-pull-up;
			};

			/omit-if-no-ref/ uart7_tx_pm9: uart7_tx_pm9 {
				pinmux = <STM32_PINMUX('M', 9, AF7)>;
				bias-pull-up;
			};

			/* UCPD */

			/omit-if-no-ref/ ucpd1_cc1_pm0: ucpd1_cc1_pm0 {
				pinmux = <STM32_PINMUX('M', 0, ANALOG)>;
			};

			/omit-if-no-ref/ ucpd1_cc2_pm1: ucpd1_cc2_pm1 {
				pinmux = <STM32_PINMUX('M', 1, ANALOG)>;
			};

			/* USB_OTG_FS */

			/omit-if-no-ref/ usb_otg_fs_sof_pa8: usb_otg_fs_sof_pa8 {
				pinmux = <STM32_PINMUX('A', 8, AF10)>;
			};

			/omit-if-no-ref/ usb_otg_fs_dp_pm11: usb_otg_fs_dp_pm11 {
				pinmux = <STM32_PINMUX('M', 11, AF10)>;
			};

			/omit-if-no-ref/ usb_otg_fs_dm_pm12: usb_otg_fs_dm_pm12 {
				pinmux = <STM32_PINMUX('M', 12, AF10)>;
			};

			/omit-if-no-ref/ usb_otg_fs_id_pm13: usb_otg_fs_id_pm13 {
				pinmux = <STM32_PINMUX('M', 13, AF10)>;
			};

			/omit-if-no-ref/ usb_otg_fs_vbus_pm14: usb_otg_fs_vbus_pm14 {
				pinmux = <STM32_PINMUX('M', 14, AF10)>;
			};

			/* USB_OTG_HS */

			/omit-if-no-ref/ usb_otg_hs_sof_pa4: usb_otg_hs_sof_pa4 {
				pinmux = <STM32_PINMUX('A', 4, AF10)>;
			};

			/omit-if-no-ref/ usb_otg_hs_dm_pm5: usb_otg_hs_dm_pm5 {
				pinmux = <STM32_PINMUX('M', 5, AF10)>;
			};

			/omit-if-no-ref/ usb_otg_hs_dp_pm6: usb_otg_hs_dp_pm6 {
				pinmux = <STM32_PINMUX('M', 6, AF10)>;
			};

			/omit-if-no-ref/ usb_otg_hs_vbus_pm8: usb_otg_hs_vbus_pm8 {
				pinmux = <STM32_PINMUX('M', 8, AF10)>;
			};

			/omit-if-no-ref/ usb_otg_hs_id_pm9: usb_otg_hs_id_pm9 {
				pinmux = <STM32_PINMUX('M', 9, AF10)>;
			};

			/* XSPIM */

			/omit-if-no-ref/ xspim_p1_ncs1_po0: xspim_p1_ncs1_po0 {
				pinmux = <STM32_PINMUX('O', 0, AF9)>;
				slew-rate = "very-high-speed";
			};

			/omit-if-no-ref/ xspim_p1_ncs2_po1: xspim_p1_ncs2_po1 {
				pinmux = <STM32_PINMUX('O', 1, AF9)>;
				slew-rate = "very-high-speed";
			};

			/omit-if-no-ref/ xspim_p1_dqs0_po2: xspim_p1_dqs0_po2 {
				pinmux = <STM32_PINMUX('O', 2, AF9)>;
				slew-rate = "very-high-speed";
			};

			/omit-if-no-ref/ xspim_p1_clk_po4: xspim_p1_clk_po4 {
				pinmux = <STM32_PINMUX('O', 4, AF9)>;
				slew-rate = "very-high-speed";
			};

			/omit-if-no-ref/ xspim_p1_nclk_po5: xspim_p1_nclk_po5 {
				pinmux = <STM32_PINMUX('O', 5, AF9)>;
				slew-rate = "very-high-speed";
			};

			/omit-if-no-ref/ xspim_p1_io0_pp0: xspim_p1_io0_pp0 {
				pinmux = <STM32_PINMUX('P', 0, AF9)>;
				slew-rate = "very-high-speed";
			};

			/omit-if-no-ref/ xspim_p1_io1_pp1: xspim_p1_io1_pp1 {
				pinmux = <STM32_PINMUX('P', 1, AF9)>;
				slew-rate = "very-high-speed";
			};

			/omit-if-no-ref/ xspim_p1_io2_pp2: xspim_p1_io2_pp2 {
				pinmux = <STM32_PINMUX('P', 2, AF9)>;
				slew-rate = "very-high-speed";
			};

			/omit-if-no-ref/ xspim_p1_io3_pp3: xspim_p1_io3_pp3 {
				pinmux = <STM32_PINMUX('P', 3, AF9)>;
				slew-rate = "very-high-speed";
			};

			/omit-if-no-ref/ xspim_p1_io4_pp4: xspim_p1_io4_pp4 {
				pinmux = <STM32_PINMUX('P', 4, AF9)>;
				slew-rate = "very-high-speed";
			};

			/omit-if-no-ref/ xspim_p1_io5_pp5: xspim_p1_io5_pp5 {
				pinmux = <STM32_PINMUX('P', 5, AF9)>;
				slew-rate = "very-high-speed";
			};

			/omit-if-no-ref/ xspim_p1_io6_pp6: xspim_p1_io6_pp6 {
				pinmux = <STM32_PINMUX('P', 6, AF9)>;
				slew-rate = "very-high-speed";
			};

			/omit-if-no-ref/ xspim_p1_io7_pp7: xspim_p1_io7_pp7 {
				pinmux = <STM32_PINMUX('P', 7, AF9)>;
				slew-rate = "very-high-speed";
			};

		};
	};
};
